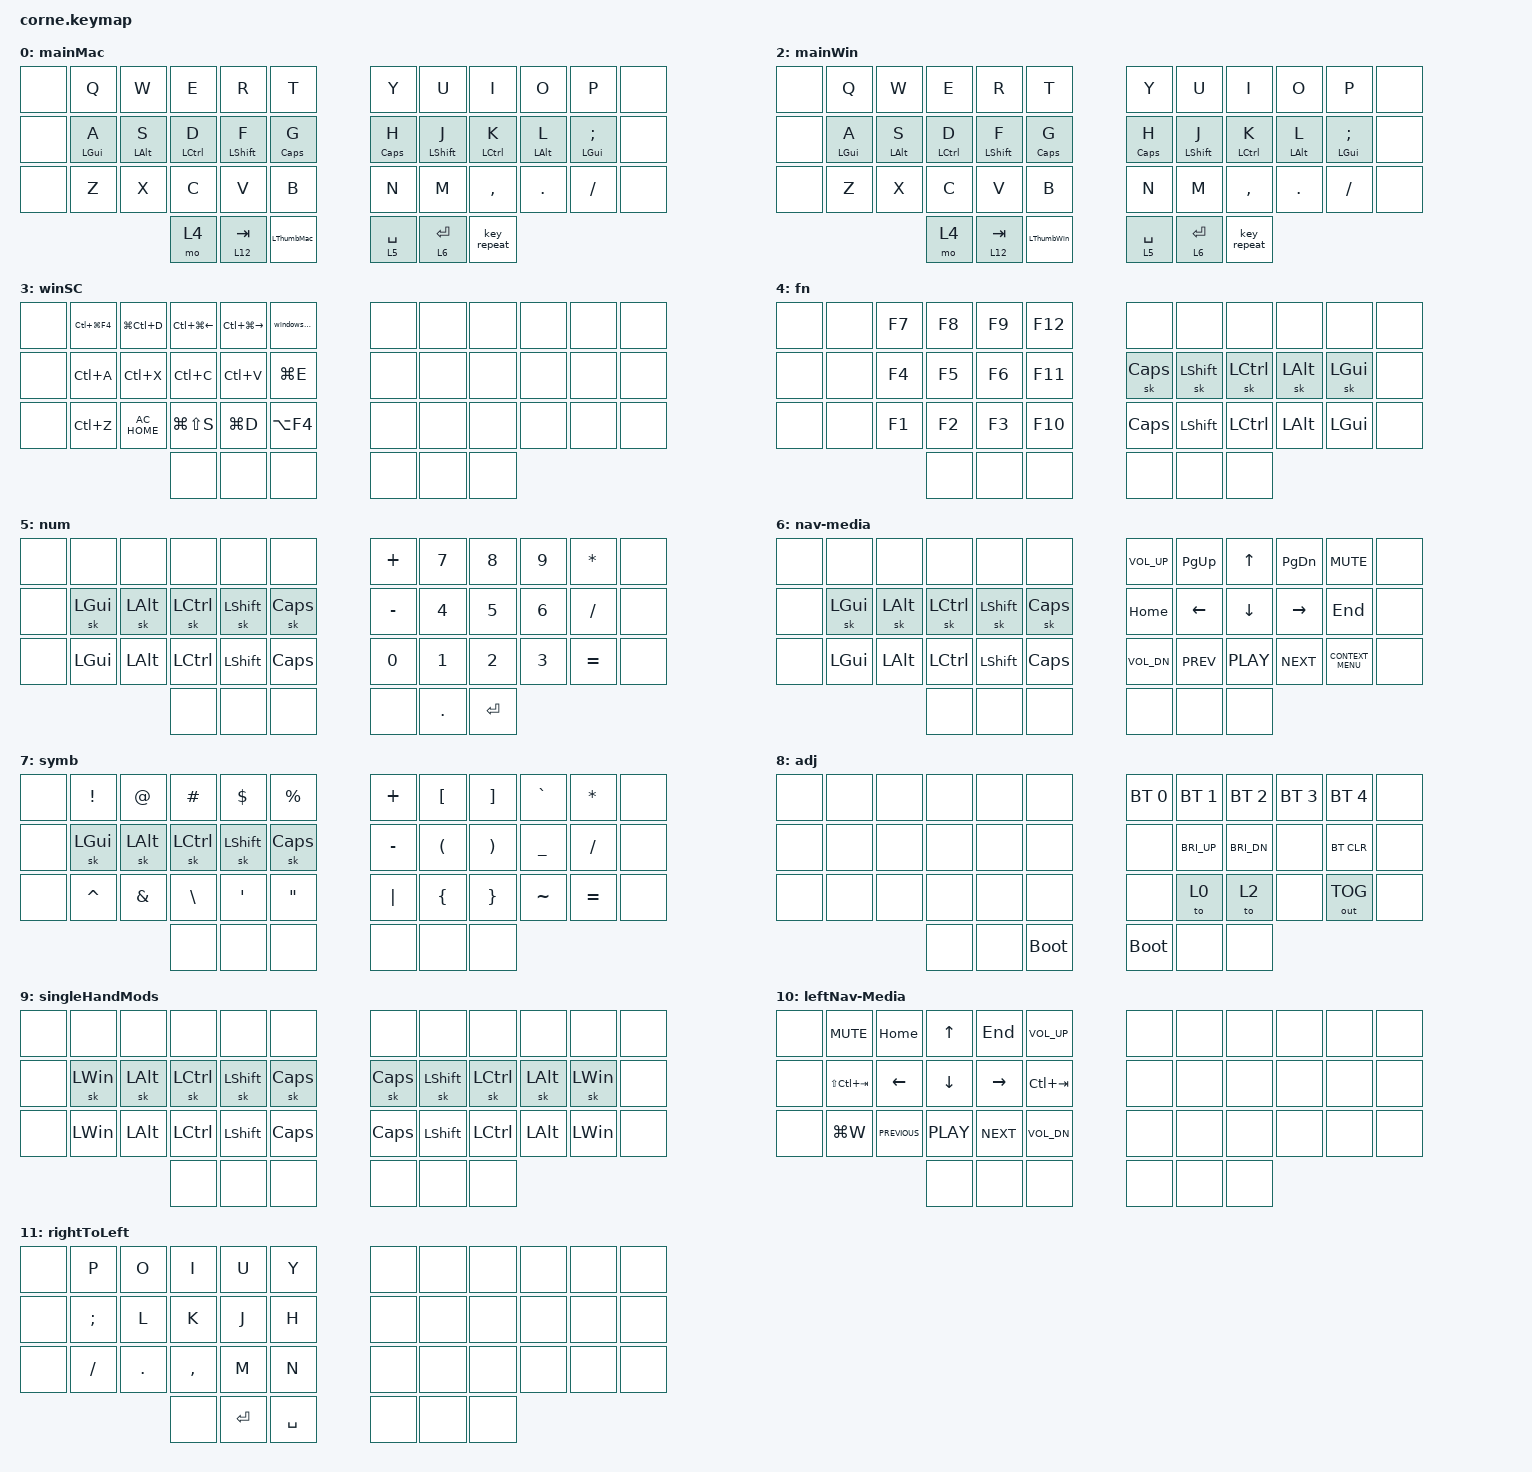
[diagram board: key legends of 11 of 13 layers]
#define ZMK_POINTING_DEFAULT_MOVE_VAL 1500  // default: 600
#define ZMK_POINTING_DEFAULT_SCRL_VAL 20    // default: 10

#include <behaviors.dtsi>
#include <dt-bindings/zmk/bt.h>
#include <dt-bindings/zmk/keys.h>
#include <dt-bindings/zmk/outputs.h>

&sk {
    quick-release;
    release-after-ms = <800>;
    lazy;
};

&lt {
    require-prior-idle-ms = <40>;
    flavor = "balanced";
};

/ {
    combos {
        compatible = "zmk,combos";

        escL {
            timeout-ms = <50>;
            bindings = <&kp ESCAPE>;
            key-positions = <3 4>;
            require-prior-idle-ms = <100>;
        };

        backR {
            bindings = <&kp BACKSPACE>;
            key-positions = <19 20>;
            timeout-ms = <50>;
            require-prior-idle-ms = <100>;
        };

        backL {
            bindings = <&kp BACKSPACE>;
            key-positions = <16 15>;
            timeout-ms = <50>;
            require-prior-idle-ms = <100>;
        };

        questionR {
            bindings = <&kp QUESTION>;
            key-positions = <33 32>;
            timeout-ms = <60>;
            require-prior-idle-ms = <80>;
        };

        wordDelMac {
            bindings = <&kp LA(BACKSPACE)>;
            key-positions = <15 14>;
            timeout-ms = <50>;
            require-prior-idle-ms = <100>;
            layers = <0>;
        };

        delR {
            bindings = <&kp DELETE>;
            key-positions = <31 32>;
            timeout-ms = <50>;
            require-prior-idle-ms = <100>;
        };

        wordDelRMac {
            bindings = <&kp LA(BACKSPACE)>;
            key-positions = <20 21>;
            timeout-ms = <50>;
            require-prior-idle-ms = <100>;
            layers = <0>;
        };

        capsWord {
            bindings = <&caps_word>;
            key-positions = <16 19>;
            timeout-ms = <150>;
            require-prior-idle-ms = <100>;
        };

        delL {
            bindings = <&kp DELETE>;
            key-positions = <27 28>;
            timeout-ms = <50>;
            require-prior-idle-ms = <100>;
        };

        toSymb {
            bindings = <&mo 7>;
            key-positions = <38 39>;
            timeout-ms = <50>;
            slow-release;
            require-prior-idle-ms = <100>;
        };

        quotes {
            bindings = <&kp SINGLE_QUOTE>;
            key-positions = <8 9>;
            timeout-ms = <50>;
            require-prior-idle-ms = <100>;
        };

        leftEnter {
            bindings = <&kp ENTER>;
            key-positions = <26 27>;
            timeout-ms = <50>;
            require-prior-idle-ms = <100>;
        };

        Rhand {
            bindings = <&mo 9>;
            key-positions = <16 37>;
            timeout-ms = <50>;
            slow-release;
        };

        LHand {
            bindings = <&mo 9>;
            key-positions = <19 40>;
            timeout-ms = <50>;
            slow-release;
        };

        toLeftNav-Media {
            bindings = <&mo 10>;
            key-positions = <38 2 3 4>;
            timeout-ms = <180>;
            slow-release;
            require-prior-idle-ms = <80>;
        };

        toAdj {
            bindings = <&mo 8>;
            key-positions = <1 5>;
            timeout-ms = <180>;
            slow-release;
            require-prior-idle-ms = <80>;
        };

        appWindows {
            bindings = <&kp LA(LC(DOWN))>;
            key-positions = <13 37>;
            timeout-ms = <50>;
            slow-release;
        };

        moRightToLeft {
            bindings = <&sl 11>;
            key-positions = <14 15 16>;
            timeout-ms = <50>;
            slow-release;
            require-prior-idle-ms = <100>;
        };

        wordDelWin {
            bindings = <&kp LC(BACKSPACE)>;
            key-positions = <20 21>;
            timeout-ms = <50>;
            require-prior-idle-ms = <100>;
            layers = <2>;
        };

        wordDelWinL {
            bindings = <&kp LC(BACKSPACE)>;
            key-positions = <15 14>;
            timeout-ms = <50>;
            require-prior-idle-ms = <100>;
            layers = <2>;
        };

        toFn {
            bindings = <&mo 4>;
            key-positions = <14 15 16 38>;
            timeout-ms = <50>;
            slow-release;
            require-prior-idle-ms = <100>;
        };

        leftQuestion {
            bindings = <&kp QUESTION>;
            key-positions = <2 3>;
            require-prior-idle-ms = <40>;
            timeout-ms = <70>;
        };

        openRecentlyClosed {
            bindings = <&kp LS(LG(T))>;
            key-positions = <1 2>;
            require-prior-idle-ms = <40>;
            timeout-ms = <70>;
        };

        newTab {
            bindings = <&kp LG(T)>;
            key-positions = <2 4>;
            require-prior-idle-ms = <40>;
            timeout-ms = <70>;
        };
    };

    behaviors {
        hmr: hmr {
            compatible = "zmk,behavior-hold-tap";
            #binding-cells = <2>;
            label = "hmr";
            bindings = <&kp>, <&kp>;

            tapping-term-ms = <279>;
            hold-trigger-key-positions = <0 1 2 3 4 5 12 13 14 15 16 17 24 25 26 27 28 29 36 37 38 39 40 41>;
            hold-trigger-on-release;             // delay positional check until key-release
            flavor = "balanced";
            require-prior-idle-ms = <200>;
            require-prior-idle-ms = <150>;
            quick-tap-ms = <175>;
        };

        hml: hml {
            compatible = "zmk,behavior-hold-tap";
            #binding-cells = <2>;
            label = "hml";
            bindings = <&kp>, <&kp>;

            tapping-term-ms = <280>;
            hold-trigger-key-positions = <6 7 8 9 10 11 18 19 20 21 22 23 30 31 32 33 34 35 39 40 41 36 37 38>;
            hold-trigger-on-release;
            flavor = "balanced";
            require-prior-idle-ms = <200>;
            quick-tap-ms = <175>;
        };

        tapSk_holdLayer: tapSk_holdLayer {
            compatible = "zmk,behavior-hold-tap";
            label = "TAPSK_HOLDLAYER";
            bindings = <&mo>, <&sk>;

            #binding-cells = <2>;
            tapping-term-ms = <80>;
            flavor = "tap-preferred";
            hold-while-undecided;
        };

        LThumbMac: LThumbMac {
            compatible = "zmk,behavior-tap-dance";
            label = "LTHUMBMAC";
            #binding-cells = <0>;
            bindings = <&tapSk_holdLayer 1 LEFT_SHIFT>, <&lt 3 LG(SPACE)>;

            tapping-term-ms = <380>;
        };

        tapToHoldMo: tapToHoldMo {
            compatible = "zmk,behavior-hold-tap";
            label = "TAPTOHOLDMO";
            #binding-cells = <2>;
            tapping-term-ms = <150>;
            flavor = "tap-preferred";
            hold-while-undecided;
            bindings = <&mo>, <&to>;
        };

        LThumbWin: LThumbWin {
            compatible = "zmk,behavior-tap-dance";
            label = "LTHUMBWIN";
            #binding-cells = <0>;
            bindings = <&tapSk_holdLayer 3 LEFT_SHIFT>, <&lt 1 LEFT_WIN>;

            tapping-term-ms = <380>;
        };
    };

    macros {
        windowsMissionControl: new_macro {
            compatible = "zmk,behavior-macro";
            #binding-cells = <0>;
            bindings =
                <&macro_press>,
                <&kp LEFT_WIN>,
                <&macro_tap>,
                <&kp TAB>,
                <&macro_release>,
                <&kp LEFT_WIN>;

            label = "NEW_MACRO";
        };
    };

    keymap {
        compatible = "zmk,keymap";

        mainMac {
            bindings = <
&none  &kp Q            &kp W            &kp E                &kp R              &kp T          &kp Y        &kp U              &kp I                &kp O            &kp P                    &none
&none  &hml LEFT_GUI A  &hml LEFT_ALT S  &hml LEFT_CONTROL D  &hml LEFT_SHIFT F  &hml CLCK G    &hmr CLCK H  &hmr LEFT_SHIFT J  &hmr LEFT_CONTROL K  &hmr LEFT_ALT L  &hmr LEFT_GUI SEMICOLON  &none
&none  &kp Z            &kp X            &kp C                &kp V              &kp B          &kp N        &kp M              &kp COMMA            &kp DOT          &kp SLASH                &none
                                         &mo 4                &lt 12 TAB         &LThumbMac     &lt 5 SPACE  &lt 6 RET          &key_repeat
            >;
        };

        macSC {
            bindings = <
&none  &kp LS(LC(LG(A)))  &kp LG(LS(LC(B)))  &kp LC(LG(LA(A)))         &kp LC(LG(LA(B)))     &kp LG(LC(D))    &none  &none  &none  &none  &none  &none
&none  &kp LG(A)          &kp LG(X)          &kp LG(C)                 &kp LG(V)             &kp LG(LC(F))    &none  &none  &none  &none  &none  &none
&none  &kp LG(Z)          &kp LG(LS(N5))     &kp LG(LS(LC(NUMBER_4)))  &kp LG(D)             &kp LG(W)        &none  &none  &none  &none  &none  &none
                                             &none                     &kp LG(LEFT_BRACKET)  &none            &none  &none  &none
            >;
        };

        mainWin {
            bindings = <
&none  &kp Q            &kp W            &kp E                &kp R              &kp T          &kp Y        &kp U              &kp I                &kp O            &kp P                    &none
&none  &hml LEFT_GUI A  &hml LEFT_ALT S  &hml LEFT_CONTROL D  &hml LEFT_SHIFT F  &hml CLCK G    &hmr CLCK H  &hmr LEFT_SHIFT J  &hmr LEFT_CONTROL K  &hmr LEFT_ALT L  &hmr LEFT_GUI SEMICOLON  &none
&none  &kp Z            &kp X            &kp C                &kp V              &kp B          &kp N        &kp M              &kp COMMA            &kp DOT          &kp SLASH                &none
                                         &mo 4                &lt 12 TAB         &LThumbWin     &lt 5 SPACE  &lt 6 RET          &key_repeat
            >;
        };

        winSC {
            bindings = <
&none  &kp LC(LG(F4))  &kp LG(LC(D))  &kp LC(LG(LEFT))  &kp LC(LG(RIGHT))  &windowsMissionControl    &none  &none  &none  &none  &none  &none
&none  &kp LC(A)       &kp LC(X)      &kp LC(C)         &kp LC(V)          &kp LG(E)                 &none  &none  &none  &none  &none  &none
&none  &kp LC(Z)       &kp C_AC_HOME  &kp LG(LS(S))     &kp LG(D)          &kp LA(F4)                &none  &none  &none  &none  &none  &none
                                      &none             &none              &none                     &none  &none  &none
            >;
        };

        fn {
            bindings = <
&none  &none  &kp F7  &kp F8  &kp F9  &kp F12    &none     &none           &none      &none     &none         &none
&none  &none  &kp F4  &kp F5  &kp F6  &kp F11    &sk CLCK  &sk LEFT_SHIFT  &sk LCTRL  &sk LALT  &sk LEFT_GUI  &none
&none  &none  &kp F1  &kp F2  &kp F3  &kp F10    &kp CAPS  &kp LEFT_SHIFT  &kp LCTRL  &kp LALT  &kp LEFT_GUI  &none
                      &none   &none   &none      &none     &none           &none
            >;
        };

        num {
            bindings = <
&none  &none         &none     &none      &none           &none       &kp PLUS   &kp N7      &kp N8     &kp N9  &kp STAR   &none
&none  &sk LEFT_GUI  &sk LALT  &sk LCTRL  &sk LEFT_SHIFT  &sk CLCK    &kp MINUS  &kp N4      &kp N5     &kp N6  &kp SLASH  &none
&none  &kp LEFT_GUI  &kp LALT  &kp LCTRL  &kp LEFT_SHIFT  &kp CLCK    &kp N0     &kp N1      &kp N2     &kp N3  &kp EQUAL  &none
                               &none      &none           &none       &none      &kp PERIOD  &kp ENTER
            >;
        };

        nav-media {
            bindings = <
&none  &none         &none     &none      &none           &none       &kp C_VOL_UP  &kp PG_UP   &kp UP      &kp PG_DN   &kp C_MUTE          &none
&none  &sk LEFT_GUI  &sk LALT  &sk LCTRL  &sk LEFT_SHIFT  &sk CLCK    &kp HOME      &kp LEFT    &kp DOWN    &kp RIGHT   &kp END             &none
&none  &kp LEFT_GUI  &kp LALT  &kp LCTRL  &kp LEFT_SHIFT  &kp CLCK    &kp C_VOL_DN  &kp C_PREV  &kp C_PLAY  &kp C_NEXT  &kp K_CONTEXT_MENU  &none
                               &none      &none           &none       &none         &none       &none
            >;
        };

        symb {
            bindings = <
&none  &kp EXCL      &kp AT    &kp HASH       &kp DLLR          &kp PERCENT          &kp PLUS   &kp LEFT_BRACKET      &kp RIGHT_BRACKET      &kp GRAVE  &kp STAR   &none
&none  &sk LEFT_GUI  &sk LALT  &sk LCTRL      &sk LEFT_SHIFT    &sk CLCK             &kp MINUS  &kp LEFT_PARENTHESIS  &kp RIGHT_PARENTHESIS  &kp UNDER  &kp SLASH  &none
&none  &kp CARET     &kp AMPS  &kp BACKSLASH  &kp SINGLE_QUOTE  &kp DOUBLE_QUOTES    &kp PIPE   &kp LEFT_BRACE        &kp RIGHT_BRACE        &kp TILDE  &kp EQUAL  &none
                               &none          &none             &none                &none      &none                 &none
            >;
        };

        adj {
            bindings = <
&none  &none  &none  &none  &none  &none          &bt BT_SEL 0  &bt BT_SEL 1  &bt BT_SEL 2  &bt BT_SEL 3  &bt BT_SEL 4  &none
&none  &none  &none  &none  &none  &none          &none         &kp C_BRI_UP  &kp C_BRI_DN  &none         &bt BT_CLR    &none
&none  &none  &none  &none  &none  &none          &none         &to 0         &to 2         &none         &out OUT_TOG  &none
                     &none  &none  &bootloader    &bootloader   &none         &none
            >;
        };

        singleHandMods {
            bindings = <
&none  &none         &none     &none      &none      &none       &none     &none      &none      &none     &none         &none
&none  &sk LEFT_WIN  &sk LALT  &sk LCTRL  &sk LSHFT  &sk CLCK    &sk CLCK  &sk LSHFT  &sk LCTRL  &sk LALT  &sk LEFT_WIN  &none
&none  &kp LEFT_WIN  &kp LALT  &kp LCTRL  &kp LSHFT  &kp CLCK    &kp CLCK  &kp LSHFT  &kp LCTRL  &kp LALT  &kp LEFT_WIN  &none
                               &none      &none      &none       &none     &none      &none
            >;
        };

        leftNav-Media {
            bindings = <
&none  &kp C_MUTE       &kp HOME        &kp UP      &kp END     &kp C_VOLUME_UP    &none  &none  &none  &none  &none  &none
&none  &kp LS(LC(TAB))  &kp LEFT        &kp DOWN    &kp RIGHT   &kp LC(TAB)        &none  &none  &none  &none  &none  &none
&none  &kp LG(W)        &kp C_PREVIOUS  &kp C_PLAY  &kp C_NEXT  &kp C_VOL_DN       &none  &none  &none  &none  &none  &none
                                        &none       &none       &none              &none  &none  &none
            >;
        };

        rightToLeft {
            bindings = <
&none  &kp P     &kp O    &kp I      &kp U      &kp Y        &none  &none  &none  &none  &none  &none
&none  &kp SEMI  &kp L    &kp K      &kp J      &kp H        &none  &none  &none  &none  &none  &none
&none  &kp FSLH  &kp DOT  &kp COMMA  &kp M      &kp N        &none  &none  &none  &none  &none  &none
                          &none      &kp ENTER  &kp SPACE    &none  &none  &none
            >;
        };

        appsSC {
            bindings = <
&none  &kp LC(LG(LA(LS(Q))))  &kp LC(LG(LA(LS(W))))  &kp LC(LG(LA(LS(E))))  &kp LC(LG(LA(LS(R))))  &kp LC(LG(LA(LS(T))))    &kp LC(LG(LA(LS(Y))))  &kp LC(LG(LA(LS(U))))  &kp LC(LG(LA(LS(I))))  &kp LC(LG(LA(LS(O))))       &kp LC(LG(LA(LS(P))))          &none
&none  &kp LC(LG(LA(LS(A))))  &kp LC(LG(LA(LS(S))))  &kp LC(LG(LA(LS(D))))  &kp LC(LG(LA(LS(F))))  &kp LC(LG(LA(LS(G))))    &kp LC(LG(LA(LS(H))))  &kp LC(LG(LA(LS(J))))  &kp LC(LG(LA(LS(K))))  &kp LC(LG(LA(LS(L))))       &kp LC(LG(LA(LS(SEMICOLON))))  &none
&none  &kp LC(LG(LA(LS(Z))))  &kp LC(LG(LA(LS(X))))  &kp LC(LG(LA(LS(C))))  &kp LC(LG(LA(LS(V))))  &kp LC(LG(LA(LS(B))))    &kp LC(LG(LA(LS(N))))  &kp LC(LG(LA(LS(M))))  &kp LC(COMMA)          &kp LC(LG(LA(LS(PERIOD))))  &kp LC(LG(LA(LS(SLASH))))      &none
                                                     &none                  &none                  &none                    &none                  &none                  &none
            >;
        };
    };
};
